# MSS_DCAN register map
Vendor: Texas Instruments
Registers are 32-bit, read-only, no defined reset value unless marked. A register's access mark holds for its fields unless they carry their own. Offsets are as the file gives them; [hi:lo] are bit positions; {n}, {i} and the like mark numbered series; 'fields as' and 'values as' point back to an identical list.

## MSS_DCAN (part 2 of 2)
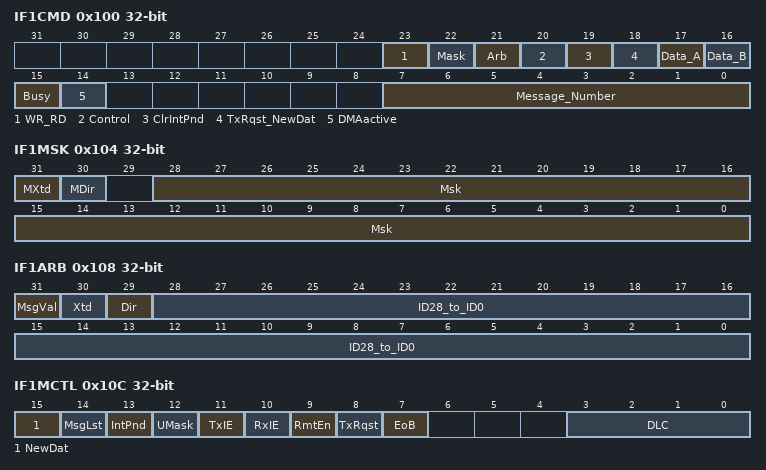
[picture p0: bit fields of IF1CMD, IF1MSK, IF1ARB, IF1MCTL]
0x100 IF1CMD access per field — IF1 Command Register The IF1 Command Register (IF1CMD) configures and initiates the transfer between the IF1 register sets and the message RAM. It is configurable which portions of the message object should be transferred. A transfer is started when the CPU writes the message number to bits [7:0] of the IF1 command register. With this write operation, the Busy bit is automatically set to '1' to indicate that a transfer is in progress. After 4 to 14 OCP clock cycles, the transfer between the interface register and the message RAM will be completed and the Busy bit is cleared. The maximum number of cycles is needed when the message transfer concurs with a CAN message transmission, acceptance filtering, or message storage. If the CPU writes to both IF1 command registers consecutively (request of a second transfer while first transfer is still in progress), the second transfer will start after the first one has been completed. While Busy bit is one, IF1 register sets are write protected. For debug support, the auto clear functionality of the IF1 command registers (clear of DMAactive flag by r/w) is disabled during Debug/Suspend mode. If an invalid Message Number is written to bits [7:0] of the IF1 command register, the message handler may access an implemented (valid) message object instead.
  [23] WR_RD rw — Write/Read
    1=en_2_0x1 (Direction = Write: Transfer direction is from the IF1 register set to the message object addressed by Message Number (Bits [7:0]).); 0=en_1_0x0 (Direction = Read: Transfer direction is from the message object addressed by Message Number (Bits [7:0]) to the IF1 register set.)
  [22] Mask rw — Access mask bits
    1=en_2_0x1 (Direction = Read: The mask bits (identifier mask + MDir + MXtd) will be transferred from the message object addressed by Message Number (Bits [7:0]) to the IF1 register set. Direction = Write: The mask bits (identifier mask + MDir + MXtd) will be transferred from the IF1 register set to the message object addressed by Message Number (Bits [7:0]).); 0=en_1_0x0 (Mask bits will not be changed)
  [21] Arb rw — Access arbitration bits
    1=en_2_0x1 (Direction = Read: The Arbitration bits (Identifier + Dir + Xtd + MsgVal) will be transferred from the message object addressed by Message Number (Bits [7:0]) to the corresponding IF1 register set. Direction = Write: The Arbitration bits (Identifier + Dir + Xtd + MsgVal) will be transferred from the IF1 register set to the message object addressed by Message Number (Bits [7:0]).); 0=en_1_0x0 (Arbitration bits will not be changed)
  [20] Control rw — Access control bits. If the TxRqst/NewDat bit in this register(Bit [18]) is set, the TxRqst/ NewDat bit in the IF1 message control register will be ignored.
    1=en_2_0x1 (Direction = Read: The message control bits will be transferred from the message object addressed by message number (Bits [7:0]) to the IF1 register set. Direction = Write: The message control bits will be transferred from the IF1 register set to the message object addressed by message number (Bits [7:0]).); 0=en_1_0x0 (Control bits will not be changed)
  [19] ClrIntPnd rw — Clear interrupt pending bit
    1=en_2_0x1 (Direction = Read: Clears IntPnd bit in the message object. Direction = Write: This bit is ignored. Copying of IntPnd flag from IF1 Registers to message RAM can only be controlled by the control flag (Bit [20]).); 0=en_1_0x0 (IntPnd bit will not be changed)
  [18] TxRqst_NewDat rw — Access transmission request bit. Note: If a CAN transmission is requested by setting TxRqst/NewDat in this register, the TxRqst/NewDat bits in the message object will be set to one independent of the values in IF1 message control Register. Note: A read access to a message object can be combined with the reset of the control bits IntPnd and NewDat. The values of these bits transferred to the IF1 message control register always reflect the status before resetting them.
    1=en_2_0x1 (Direction = Read: Clears NewDat bit in the message object. Direction = Write: Sets TxRqst/NewDat in message object.); 0=en_1_0x0 (Direction = Read: NewDat bit will not be changed. Direction = Write: TxRqst/NewDat bit will be handled according to the control bit.)
  [17] Data_A rw — Access Data Bytes 0 to 3.
    1=en_2_0x1 (Direction = Read: The data bytes 0-3 will be transferred from the message object addressed by the Message Number (Bits [7:0]) to the corresponding IF1 register set. Direction = Write: The data bytes 0-3 will be transferred from the IF1 register set to the message object addressed by the Message Number (Bits [7:0]). Note: The duration of the message transfer is independent of the number of bytes to be transferred.); 0=en_1_0x0 (Data Bytes 0-3 will not be changed.)
  [16] Data_B rw — Access Data Bytes 4 to 7.
    1=en_2_0x1 (Direction = Read: The data bytes 4-7 will be transferred from the message object addressed by Message Number (Bits [7:0]) to the corresponding IF1 register set. Direction = Write: The data bytes 4-7 will be transferred from the IF1 register set to the message object addressed by message number (Bits [7:0]). Note: The duration of the message transfer is independent of the number of bytes to be transferred.); 0=en_1_0x0 (Data Bytes 4-7 will not be changed.)
  [15] Busy rw — Busy flag. This bit is set to one after the message number has been written to bits 7 to 0. IF1 register set will be write protected. The bit is cleared after read/write action has been finished.
    1=en_2_0x1 (Transfer between IF1 register set and message RAM is in progress.); 0=en_1_0x0 (No transfer between IF1 register set and message RAM is in progress.)
  [14] DMAactive rw — Activation of DMA feature for subsequent internal IF1 update. Note: Due to the auto reset feature of the DMAactive bit, this bit has to be set for each subsequent DMA cycle separately.
    1=en_2_0x1 (DMA is requested after completed transfer between IF1 register set and message RAM. The DMA request remains active until the first read or write to one of the IF1 registers; an exception is a write to Message Number (Bits [7:0]) when DMAactive is one.); 0=en_1_0x0 (DMA request line is independent of IF1 activities.)
  [7:0] Message_Number rw — Number of message object in message RAM which is used for data transfer.
    81=en_5_0x51 (Invalid message numbers (value 81 to FF).); 80=en_4_0x50 (Valid message number.); 1=en_3_0x1 (Valid message numbers (value 01 to 80).); 0=en_2_0x0 (Invalid message numbers.); 0=en_1_0x0 (Invalid message number.)
0x104 IF1MSK access per field — IF1 Mask Register The bits of the IF1 mask registers mirror the mask bits of a message object. While Busy bit of IF1 command register is one, IF1 register set is write protected.
  [31] MXtd rw — Mask Extended Identifier. When 11 bit (standard) identifiers are used for a message object, the identifiers of received data frames are written into bits ID28 to ID18. For acceptance filtering, only these bits together with mask bits Msk28 to Msk18 are considered.
    1=en_2_0x1 (The extended identifier bit (IDE) is used for acceptance filtering.); 0=en_1_0x0 (The extended identifier bit (IDE) has no effect on the acceptance filtering.)
  [30] MDir rw — Mask Message Direction
    1=en_2_0x1 (The message direction bit (Dir) is used for acceptance filtering.); 0=en_1_0x0 (The message direction bit (Dir) has no effect on the acceptance filtering.)
  [28:0] Msk rw — Identifier Mask
    1=en_2_0x1 (The corresponding bit in the identifier of the message object is used for acceptance filtering.); 0=en_1_0x0 (The corresponding bit in the identifier of the message object is not used for acceptance filtering (don't care).)
0x108 IF1ARB rw — IF1 Arbitration Register The bits of the IF1 arbitration registers mirror the arbitration bits of a message object. While Busy bit of IF1 command register is one, IF1 register set is write protected.
  [31] MsgVal — Message valid. The CPU should reset the MsgVal bit of all unused Messages Objects during the initialization before it resets bit Init in the CAN control register. This bit must also be reset before the identifier ID28 to ID0, the control bits Xtd, Dir or DLC3 to DLC0 are modified, or if the messages object is no longer required.
    1=en_2_0x1 (The message object is to be used by the message handler.); 0=en_1_0x0 (The message object is ignored by the message handler.)
  [30] Xtd — Extended identifier
    1=en_2_0x1 (The 29-bit (extended) Identifier is used for this message object.); 0=en_1_0x0 (The 11-bit (standard) Identifier is used for this message object.)
  [29] Dir — Message direction
    1=en_2_0x1 (Direction = transmit: On TxRqst, the respective message object is transmitted as a data frame. On reception of a remote frame with matching identifier, the TxRqst bit of this message object is set (if RmtEn = 1).); 0=en_1_0x0 (Direction = receive: On TxRqst, a remote frame with the identifier of this message object is transmitted. On reception of a data frame with matching identifier, this message is stored in this message object.)
  [28:0] ID28_to_ID0 — Message identifier. ID28 to ID0 is equal to 29 bit identifier (extended frame) ID28 to ID18 is equal to 11 bit identifier (standard frame)
0x10C IF1MCTL rw — IF1 Message Control Register The bits of the IF1 message control registers mirror the message control bits of a message object. While Busy bit of IF1 command register is one, IF1 register set is write protected.
  [15] NewDat — New data
    1=en_2_0x1 (The message handler or the CPU has written new data into the data portion of this message object.); 0=en_1_0x0 (No new data has been written into the data portion of this message object by the message handler since the last time when this flag was cleared by the CPU.)
  [14] MsgLst — Message lost (only valid for message objects with direction = receive)
    1=en_2_0x1 (The message handler stored a new message into this object when NewDat was still set, so the previous message has been overwritten.); 0=en_1_0x0 (No message lost since the last time when this bit was reset by the CPU.)
  [13] IntPnd — Interrupt pending
    1=en_2_0x1 (This message object is the source of an interrupt. The Interrupt Identifier in the interrupt register will point to this message object if there is no other interrupt source with higher priority.); 0=en_1_0x0 (This message object is not the source of an interrupt.)
  [12] UMask — Use acceptance mask. If the UMask bit is set to one, the message object's mask bits have to be programmed during initialization of the message object before MsgVal is set to one.
    1=en_2_0x1 (Use mask (Msk[28:0], MXtd, and MDir) for acceptance filtering); 0=en_1_0x0 (Mask ignored)
  [11] TxIE — Transmit interrupt enable
    1=en_2_0x1 (IntPnd will be triggered after the successful transmission of a frame.); 0=en_1_0x0 (IntPnd will not be triggered after the successful transmission of a frame.)
  [10] RxIE — Receive interrupt enable
    1=en_2_0x1 (IntPnd will be triggered after the successful reception of a frame.); 0=en_1_0x0 (IntPnd will not be triggered after the successful reception of a frame.)
  [9] RmtEn — Remote enable
    1=en_2_0x1 (At the reception of a remote frame, TxRqst is set.); 0=en_1_0x0 (At the reception of a remote frame, TxRqst is not changed.)
  [8] TxRqst — Transmit request
    1=en_2_0x1 (The transmission of this message object is requested and is not yet done.); 0=en_1_0x0 (This message object is not waiting for a transmission.)
  [7] EoB — Data frame has 0 to 8 data bits. Note: This bit is used to concatenate multiple message objects to build a FIFO Buffer. For single message objects (not belonging to a FIFO Buffer), this bit must always be set to one.
    1=en_2_0x1 (Note: The data length code of a message object must be defined the same as in all the corresponding objects with the same identifier at other nodes. When the message handler stores a data frame, it will write the DLC to the value given by the received message.); 0=en_1_0x0 (Data frame has 8 data bytes.)
  [3:0] DLC — Data length code. Note: The data length code of a message object must be defined the same as in all the corresponding objects with the same identifier at other nodes. When the message handler stores a data frame, it will write the DLC to the value given by the received message.
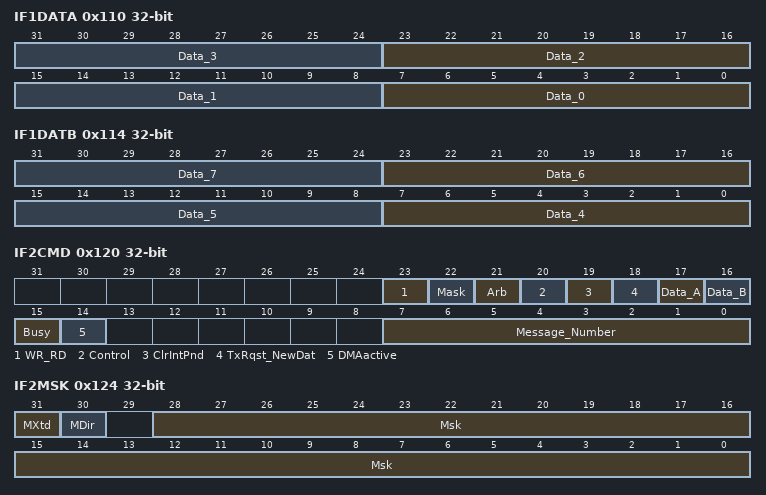
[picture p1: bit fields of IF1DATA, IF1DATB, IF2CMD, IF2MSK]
0x110 IF1DATA rw — IF1 Data A Register The data bytes of CAN messages are stored in the IF1 registers in the following order: (1) In a CAN data frame, Data 0 is the first, and Data 7 is the last byte to be transmitted or received. (2) In CAN's serial bit stream, the MSB of each byte will be transmitted first.
  [8n+7:8n] Data_{n} (n=0..3)
0x114 IF1DATB rw — IF1 Data B Register The data bytes of CAN messages are stored in the IF1 registers in the following order: (1) In a CAN data frame, Data 0 is the first, and Data 7 is the last byte to be transmitted or received. (2) In CAN's serial bit stream, the MSB of each byte will be transmitted first.
  [8n-25:8n-32] Data_{n} (n=4..7)
0x120 IF2CMD access per field — IF2 Command Register The IF2 Command Register (IF1CMD) configures and initiates the transfer between the IF2 register sets and the message RAM. It is configurable which portions of the message object should be transferred. A transfer is started when the CPU writes the message number to bits [7:0] of the IF2 command register. With this write operation, the Busy bit is automatically set to '1' to indicate that a transfer is in progress. After 4 to 14 OCP clock cycles, the transfer between the interface register and the message RAM will be completed and the Busy bit is cleared. The maximum number of cycles is needed when the message transfer concurs with a CAN message transmission, acceptance filtering, or message storage. If the CPU writes to both IF2 command registers consecutively (request of a second transfer while first transfer is still in progress), the second transfer will start after the first one has been completed. While Busy bit is one, IF2 register sets are write protected. For debug support, the auto clear functionality of the IF2 command registers (clear of DMAactive flag by r/w) is disabled during Debug/Suspend mode. If an invalid Message Number is written to bits [7:0] of the IF2 command register, the message handler may access an implemented (valid) message object instead.
  [23] WR_RD rw — Write/Read
    1=en_2_0x1 (Direction = Write: Transfer direction is from the IF2 register set to the message object addressed by Message Number (Bits [7:0]).); 0=en_1_0x0 (Direction = Read: Transfer direction is from the message object addressed by Message Number (Bits [7:0]) to the IF2 register set.)
  [22] Mask rw — Access mask bits
    1=en_2_0x1 (Direction = Read: The mask bits (identifier mask + MDir + MXtd) will be transferred from the message object addressed by Message Number (Bits [7:0]) to the IF2 register set. Direction = Write: The mask bits (identifier mask + MDir + MXtd) will be transferred from the IF2 register set to the message object addressed by Message Number (Bits [7:0]).); 0=en_1_0x0 (Mask bits will not be changed)
  [21] Arb rw — Access arbitration bits
    1=en_2_0x1 (Direction = Read: The Arbitration bits (Identifier + Dir + Xtd + MsgVal) will be transferred from the message object addressed by Message Number (Bits [7:0]) to the corresponding IF2 register set. Direction = Write: The Arbitration bits (Identifier + Dir + Xtd + MsgVal) will be transferred from the IF2 register set to the message object addressed by Message Number (Bits [7:0]).); 0=en_1_0x0 (Arbitration bits will not be changed)
  [20] Control rw — Access control bits. If the TxRqst/NewDat bit in this register(Bit [18]) is set, the TxRqst/ NewDat bit in the IF2 message control register will be ignored.
    1=en_2_0x1 (Direction = Read: The message control bits will be transferred from the message object addressed by message number (Bits [7:0]) to the IF2 register set. Direction = Write: The message control bits will be transferred from the IF2 register set to the message object addressed by message number (Bits [7:0]).); 0=en_1_0x0 (Control bits will not be changed)
  [19] ClrIntPnd rw — Clear interrupt pending bit
    1=en_2_0x1 (Direction = Read: Clears IntPnd bit in the message object. Direction = Write: This bit is ignored. Copying of IntPnd flag from IF2 Registers to message RAM can only be controlled by the control flag (Bit [20]).); 0=en_1_0x0 (IntPnd bit will not be changed)
  [18] TxRqst_NewDat rw — Access transmission request bit. Note: If a CAN transmission is requested by setting TxRqst/NewDat in this register, the TxRqst/NewDat bits in the message object will be set to one independent of the values in IF2 message control Register. Note: A read access to a message object can be combined with the reset of the control bits IntPnd and NewDat. The values of these bits transferred to the IF2 message control register always reflect the status before resetting them.
    values as IF1CMD.TxRqst_NewDat
  [17] Data_A rw — Access Data Bytes 0 to 3.
    1=en_2_0x1 (Direction = Read: The data bytes 0-3 will be transferred from the message object addressed by the Message Number (Bits [7:0]) to the corresponding IF2 register set. Direction = Write: The data bytes 0-3 will be transferred from the IF2 register set to the message object addressed by the Message Number (Bits [7:0]). Note: The duration of the message transfer is independent of the number of bytes to be transferred.); 0=en_1_0x0 (Data Bytes 0-3 will not be changed.)
  [16] Data_B rw — Access Data Bytes 4 to 7.
    1=en_2_0x1 (Direction = Read: The data bytes 4-7 will be transferred from the message object addressed by Message Number (Bits [7:0]) to the corresponding IF2 register set. Direction = Write: The data bytes 4-7 will be transferred from the IF2 register set to the message object addressed by message number (Bits [7:0]). Note: The duration of the message transfer is independent of the number of bytes to be transferred.); 0=en_1_0x0 (Data Bytes 4-7 will not be changed.)
  [15] Busy rw — Busy flag. This bit is set to one after the message number has been written to bits 7 to 0. IF2 register set will be write protected. The bit is cleared after read/write action has been finished.
    1=en_2_0x1 (Transfer between IF2 register set and message RAM is in progress.); 0=en_1_0x0 (No transfer between IF2 register set and message RAM is in progress.)
  [14] DMAactive rw — Activation of DMA feature for subsequent internal IF2 update. Note: Due to the auto reset feature of the DMAactive bit, this bit has to be set for each subsequent DMA cycle separately.
    1=en_2_0x1 (DMA is requested after completed transfer between IF2 register set and message RAM. The DMA request remains active until the first read or write to one of the IF2 registers; an exception is a write to Message Number (Bits [7:0]) when DMAactive is one.); 0=en_1_0x0 (DMA request line is independent of IF2 activities.)
  [7:0] Message_Number rw — Number of message object in message RAM which is used for data transfer.
    81=en_5_0x51 (Invalid message numbers (values 81 to FF).); 80=en_4_0x50 (Valid message number.); 1=en_3_0x1 (Valid message numbers (values 01 to 80).); 0=en_2_0x0 (Invalid message number.); 0=en_1_0x0 (Invalid message number.)
0x124 IF2MSK access per field — IF2 Mask Register The bits of the IF2 mask registers mirror the mask bits of a message object. While Busy bit of IF2 command register is one, IF2 register set is write protected.
  fields as IF1MSK
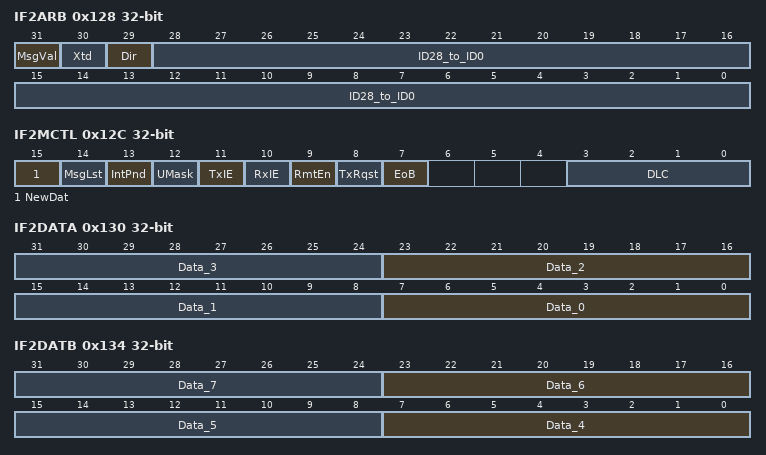
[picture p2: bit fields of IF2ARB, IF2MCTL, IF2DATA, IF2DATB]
0x128 IF2ARB rw — IF2 Arbitration Register The bits of the IF2 arbitration registers mirror the arbitration bits of a message object. While Busy bit of IF2 command register is one, IF2 register set is write protected.
  [31] MsgVal — Message valid. The CPU should reset the MsgVal bit of all unused Messages Objects during the initialization before it resets bit Init in the CAN control register. This bit must also be reset before the identifier ID28 to ID0, the control bits Xtd, Dir or DLC3 to DLC0 are modified, or if the messages object is no longer required.
    values as IF1ARB.MsgVal
  [30] Xtd — Extended identifier
    values as IF1ARB.Xtd
  [29] Dir — Message direction
    values as IF1ARB.Dir
  [28:0] ID28_to_ID0 — Message identifier. ID28 to ID0 is equal to 29-bit identifier (extended frame) ID28 to ID18 is equal to 11-bit identifier (standard frame)
0x12C IF2MCTL rw — IF2 Message Control Register The bits of the IF2 message control registers mirror the message control bits of a message object. While Busy bit of IF2 command register is one, IF2 register set is write protected.
  fields as IF1MCTL
0x130 IF2DATA rw — IF2 Data A Register The data bytes of CAN messages are stored in the IF2 registers in the following order: (1) In a CAN data frame, Data 0 is the first, and Data 7 is the last byte to be transmitted or received. (2) In CAN's serial bit stream, the MSB of each byte will be transmitted first.
  [8n+7:8n] Data_{n} (n=0..3)
0x134 IF2DATB rw — IF2 Data B Register The data bytes of CAN messages are stored in the IF2 registers in the following order: (1) In a CAN data frame, Data 0 is the first, and Data 7 is the last byte to be transmitted or received. (2) In CAN's serial bit stream, the MSB of each byte will be transmitted first.
  [8n-25:8n-32] Data_{n} (n=4..7)
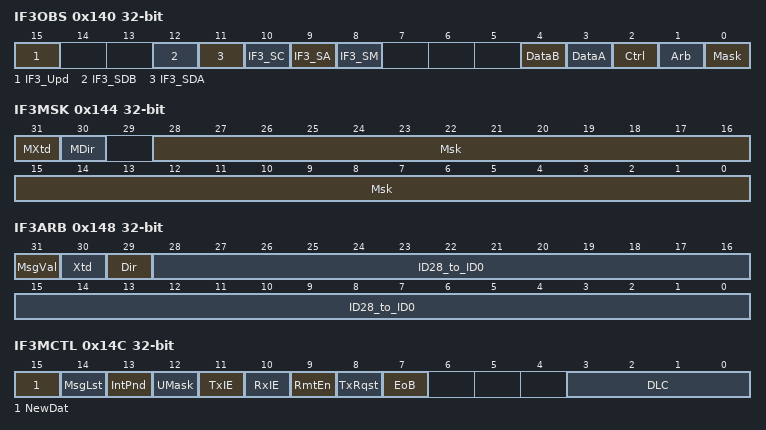
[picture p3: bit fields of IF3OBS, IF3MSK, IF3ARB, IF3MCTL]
0x140 IF3OBS access per field — IF3 Observation Register The IF3 register set can automatically be updated with received message objects without the need to initiate the transfer from message RAM by CPU. The observation flags (Bits [4:0]) in the IF3 observation register are used to determine, which data sections of the IF3 interface register set have to be read in order to complete a DMA read cycle. After all marked data sections are read, the DCAN is enabled to update the IF3 interface register set with new data. Any access order of single bytes or half-words is supported. When using byte or half-word accesses, a data section is marked as completed, if all bytes are read. Note: If IF3 Update Enable is used and no Observation flag is set, the corresponding message objects will be copied to IF3 without activating the DMA request line and without waiting for DMA read accesses. A write access to this register aborts a pending DMA cycle by resetting the DMA line and enables updating of IF3 interface register set with new data. To avoid data inconsistency, the DMA controller should be disabled before reconfiguring IF3 observation register. The status of the current read-cycle can be observed via status flags (Bits [12:8]). If an interrupt line is available for IF3, an interrupt will be generated by IF3Upd flag. See the device-specific data sheet for the availability of this interrupt source. With this interrupt, the observation status bits and the IF3Upd bit could be used by the application to realize the notification about new IF3 content in polling or interrupt mode.
  [15] IF3_Upd ro — IF3 Update Data
    1=en_2_0x1 (New data has been loaded since last IF3 read.); 0=en_1_0x0 (No new data has been loaded since last IF3 read.)
  [12] IF3_SDB ro — IF3 Status of Data B read access
    1=en_2_0x1 (Data B section has still data to be read out.); 0=en_1_0x0 (All Data B bytes are already read out, or are not marked to be read.)
  [11] IF3_SDA ro — IF3 Status of Data A read access
    1=en_2_0x1 (Data A section has still data to be read out.); 0=en_1_0x0 (All Data A bytes are already read out, or are not marked to be read.)
  [10] IF3_SC ro — IF3 Status of control bits read access
    1=en_2_0x1 (Control section has still data to be read out.); 0=en_1_0x0 (All control section bytes are already read out, or are not marked to be read.)
  [9] IF3_SA ro — IF3 Status of Arbitration data read access
    1=en_2_0x1 (Arbitration section has still data to be read out.); 0=en_1_0x0 (All Arbitration data bytes are already read out, or are not marked to be read.)
  [8] IF3_SM ro — IF3 Status of Mask data read access
    1=en_2_0x1 (Mask section has still data to be read out.); 0=en_1_0x0 (All mask data bytes are already read out, or are not marked to be read.)
  [4] DataB rw — Data B read observation
    1=en_2_0x1 (Data B section has to be read to enable next IF3 update.); 0=en_1_0x0 (Data B section has not to be read.)
  [3] DataA rw — Data A read observation
    1=en_2_0x1 (Data A section has to be read to enable next IF3 update.); 0=en_1_0x0 (Data A section has not to be read.)
  [2] Ctrl rw — Ctrl read observation
    1=en_2_0x1 (Ctrl section has to be read to enable next IF3 update.); 0=en_1_0x0 (Ctrl section has not to be read.)
  [1] Arb rw — Arbitration data read observation
    1=en_2_0x1 (Arbitration data has to be read to enable next IF3 update.); 0=en_1_0x0 (Arbitration data has not to be read.)
  [0] Mask rw — Mask data read observation
    1=en_2_0x1 (Mask data has to be read to enable next IF3 update.); 0=en_1_0x0 (Mask data has not to be read.)
0x144 IF3MSK access per field — IF3 Mask Register
  [31] MXtd ro — Mask Extended Identifier. When 11 bit (standard) identifiers are used for a message object, the identifiers of received data frames are written into bits ID28 to ID18. For acceptance filtering, only these bits together with mask bits Msk28 to Msk18 are considered.
    values as IF1MSK.MXtd
  [30] MDir ro — Mask Message Direction
    values as IF1MSK.MDir
  [28:0] Msk rw — Identifier Mask
    values as IF1MSK.Msk
0x148 IF3ARB — IF3 Arbitration Register
  [31] MsgVal — Message Valid. The CPU should reset the MsgVal bit of all unused Messages Objects during the initialization before it resets bit Init in the CAN control register. This bit must also be reset before the identifier ID28 to ID0, the control bits Xtd, Dir or DLC3 to DLC0 are modified, or if the messages object is no longer required.
    values as IF1ARB.MsgVal
  [30] Xtd — Extended Identifier
    values as IF1ARB.Xtd
  [29] Dir — Message Direction
    values as IF1ARB.Dir
  [28:0] ID28_to_ID0 — Message Identifier. ID28 to ID0 is equal to 29 bit Identifier (extended frame). ID28 to ID18 is equal to 11 bit Identifier (standard frame).
0x14C IF3MCTL — IF3 Message Control Register
  [15] NewDat — New Data
    values as IF1MCTL.NewDat
  [14] MsgLst — Message Lost (only valid for message objects with direction = receive)
    values as IF1MCTL.MsgLst
  [13] IntPnd — Interrupt Pending
    values as IF1MCTL.IntPnd
  [12] UMask — Use Acceptance Mask
    1=en_2_0x1 (Use mask (Msk[28:0], MXtd, and MDir) for acceptance filtering. If the UMask bit is set to one, the message object's mask bits have to be programmed during initialization of the message object before MsgVal is set to one.); 0=en_1_0x0 (Mask ignored)
  [11] TxIE — Transmit Interrupt enable
    values as IF1MCTL.TxIE
  [10] RxIE — Receive Interrupt enable
    values as IF1MCTL.RxIE
  [9] RmtEn — Remote enable
    values as IF1MCTL.RmtEn
  [8] TxRqst — Transmit Request
    values as IF1MCTL.TxRqst
  [7] EoB — Data frame has 0 to 8 data bits. Note: This bit is used to concatenate multiple message objects to build a FIFO Buffer. For single message objects (not belonging to a FIFO Buffer), this bit must always be set to one.
    values as IF1MCTL.EoB
  [3:0] DLC — Data Length Code. Note: The data length code of a message object must be defined the same as in all the corresponding objects with the same identifier at other nodes. When the message handler stores a data frame, it will write the DLC to the value given by the received message.
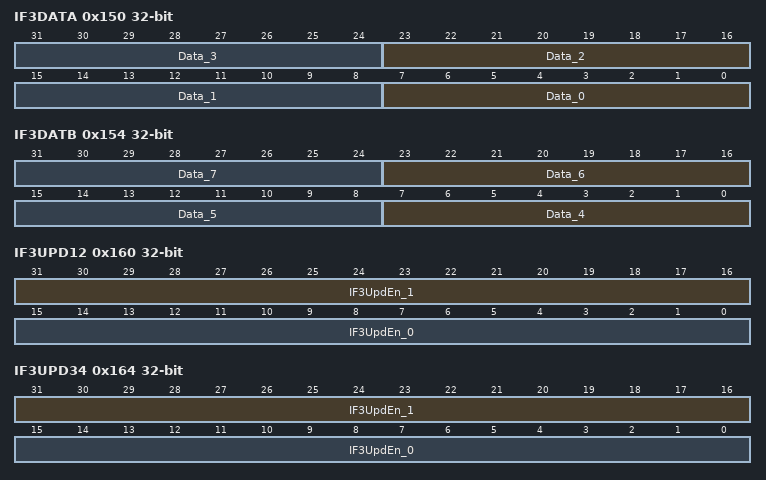
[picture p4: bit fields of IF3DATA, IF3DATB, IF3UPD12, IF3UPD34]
0x150 IF3DATA — IF3 Data A Register The data bytes of CAN messages are stored in the IF3 registers in the following order. In a CAN data frame, Data 0 is the first, and Data 7 is the last byte to be transmitted or received. In CAN's serial bit stream, the MSB of each byte will be transmitted first.
  [8n+7:8n] Data_{n} (n=0..3)
0x154 IF3DATB — IF3 Data B Register The data bytes of CAN messages are stored in the IF3 registers in the following order. In a CAN data frame, Data 0 is the first, and Data 7 is the last byte to be transmitted or received. In CAN's serial bit stream, the MSB of each byte will be transmitted first.
  [8n-25:8n-32] Data_{n} (n=4..7)
0x160 IF3UPD12 rw — IF3 Update Enable Register The automatic update functionality of the IF3 register set can be configured for each message object. A message object is enabled for automatic IF3 update, if the dedicated IF3UpdEn flag is set. This means that an active NewDat flag of this message object (e.g due to reception of a CAN frame) will trigger an automatic copy of the whole message object to IF3 register set. IF3 Update enable should not be set for transmit objects.
  [31:16] IF3UpdEn_1 — IF3 Update Enabled (for all message objects)
    1=en_2_0x1 (Automatic IF3 update is enabled for this message object. A message object is scheduled to be copied to IF3 register set, if NewDat flag of the message object is active.); 0=en_1_0x0 (Automatic IF3 update is disabled for this message object.)
  [15:0] IF3UpdEn_0 — IF3 Update Enabled (for all message objects)
    values as IF3UpdEn_1
0x164 IF3UPD34 rw — IF3 Update Enable Register The automatic update functionality of the IF3 register set can be configured for each message object. A message object is enabled for automatic IF3 update, if the dedicated IF3UpdEn flag is set. This means that an active NewDat flag of this message object (e.g due to reception of a CAN frame) will trigger an automatic copy of the whole message object to IF3 register set. IF3 Update enable should not be set for transmit objects.
  fields as IF3UPD12
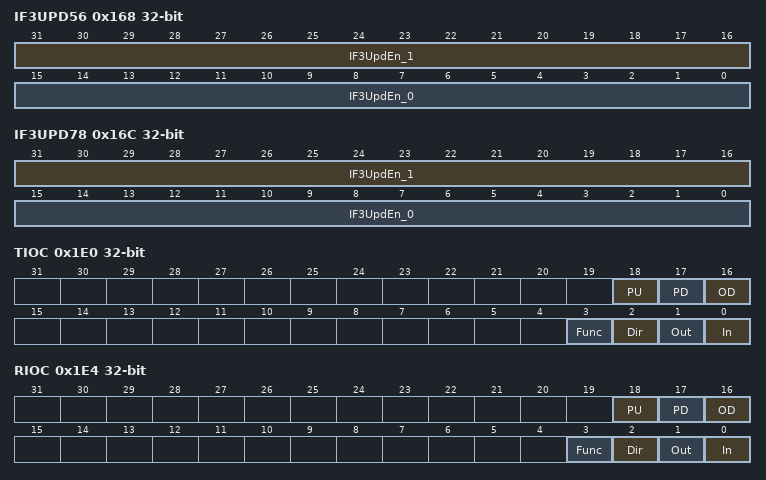
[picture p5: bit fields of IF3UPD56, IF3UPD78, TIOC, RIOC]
0x168 IF3UPD56 rw — IF3 Update Enable Register The automatic update functionality of the IF3 register set can be configured for each message object. A message object is enabled for automatic IF3 update, if the dedicated IF3UpdEn flag is set. This means that an active NewDat flag of this message object (e.g due to reception of a CAN frame) will trigger an automatic copy of the whole message object to IF3 register set. IF3 Update enable should not be set for transmit objects.
  fields as IF3UPD12
0x16C IF3UPD78 rw — IF3 Update Enable Register The automatic update functionality of the IF3 register set can be configured for each message object. A message object is enabled for automatic IF3 update, if the dedicated IF3UpdEn flag is set. This means that an active NewDat flag of this message object (e.g due to reception of a CAN frame) will trigger an automatic copy of the whole message object to IF3 register set. IF3 Update enable should not be set for transmit objects.
  fields as IF3UPD12
0x1E0 TIOC access per field — CAN TX IO Control Register The CAN_TX pin of the DCAN module can be used as general purpose IO pin if CAN function is not needed. The values of the IO control registers are only writable if Init bit of the CAN control register is set. The OD, Func, Dir and Out bits of the CAN TX IO control register are forced to certain values when Init bit of CAN control register is reset (see bit descriptions).
  [18] PU rw — CAN_TX pull up/pull down select. This bit is only active when CAN_TX is configured to be an input.
    1=en_2_0x1 (CAN_TX pull up is selected, when pull logic is active (PD = 0).); 0=en_1_0x0 (CAN_TX pull down is selected, when pull logic is active (PD = 0).)
  [17] PD rw — CAN_TX pull disable. This bit is only active when CAN_TX is configured to be an input.
    1=en_2_0x1 (CAN_TX pull is disabled); 0=en_1_0x0 (CAN_TX pull is active)
  [16] OD rw — CAN_TX open drain enable. This bit is only active when CAN_TX is configured to be in GIO mode (TIOC.Func=0). Forced to '0' if Init bit of CAN control register is reset.
    1=en_2_0x1 (The CAN_TX pin is configured in open drain mode.); 0=en_1_0x0 (The CAN_TX pin is configured in push/pull mode.)
  [3] Func rw — CAN_TX function. This bit changes the function of the CAN_TX pin. Forced to '1' if Init bit of CAN control register is reset.
    1=en_2_0x1 (CAN_TX pin is in functional mode (as an output to transmit CAN data).); 0=en_1_0x0 (CAN_TX pin is in GIO mode.)
  [2] Dir rw — CAN_TX data direction. This bit controls the direction of the CAN_TX pin when it is configured to be in GIO mode only (TIOC.Func=0). Forced to '1' if Init bit of CAN control register is reset.
    1=en_2_0x1 (The CAN_TX pin is an output); 0=en_1_0x0 (The CAN_TX pin is an input.)
  [1] Out rw — CAN_TX data out write. This bit is only active when CAN_TX pin is configured to be in GIO mode (TIOC.Func = 0) and configured to be an output pin (TIOC.Dir = 1). The value of this bit indicates the value to be output to the CAN_TX pin. Forced to Tx output of the CAN core, if Init bit of CAN control register is reset.
    1=en_2_0x1 (The CAN_TX pin is driven to logic high); 0=en_1_0x0 (The CAN_TX pin is driven to logic low)
  [0] In ro — CAN_TX data in. Note: When CAN_TX pin is connected to a CAN transceiver, an external pullup resistor has to be used to ensure that the CAN bus will not be disturbed (e.g. while reset of the DCAN module).
    1=en_2_0x1 (The CAN_TX pin is at logic high); 0=en_1_0x0 (The CAN_TX pin is at logic low)
0x1E4 RIOC access per field — CAN RX IO Control Register The CAN_RX pin of the DCAN module can be used as general purpose IO pin if CAN function is not needed. The values of the IO control registers are writable only if Init bit of CAN control register is set. The OD, Func and Dir bits of the CAN RX IO control register are forced to certain values when the Init bit of CAN control register is reset (see bit descriptions).
  [18] PU rw — CAN_RX pull up/pull down select. This bit is only active when CAN_RX is configured to be an input.
    1=en_2_0x1 (CAN_T=RX pull up is selected, when pull logic is active(PD = 0).); 0=en_1_0x0 (CAN_RX pull down is selected, when pull logic is active (PD = 0).)
  [17] PD rw — CAN_RX pull disable. This bit is only active when CAN_TX is configured to be an input.
    1=en_2_0x1 (CAN_RX pull is disabled); 0=en_1_0x0 (CAN_RX pull is active)
  [16] OD rw — CAN_RX open drain enable. This bit is only active when CAN_RX is configured to be in GIO mode (TIOC.Func=0). Forced to '0' if Init bit of CAN control register is reset.
    1=en_2_0x1 (The CAN_RX pin is configured in open drain mode.); 0=en_1_0x0 (The CAN_RX pin is configured in push/pull mode.)
  [3] Func rw — CAN_RX function. This bit changes the function of the CAN_RX pin. Forced to '1' if Init bit of CAN control register is reset.
    1=en_2_0x1 (CAN_RX pin is in functional mode (as an output to transmit CAN data).); 0=en_1_0x0 (CAN_RX pin is in GIO mode.)
  [2] Dir rw — CAN_RX data direction. This bit controls the direction of the CAN_RX pin when it is configured to be in GIO mode only (TIOC.Func=0). Forced to '1' if Init bit of CAN control register is reset.
    1=en_2_0x1 (The CAN_RX pin is an output); 0=en_1_0x0 (The CAN_RX pin is an input.)
  [1] Out rw — CAN_RX data out write. This bit is only active when CAN_RX pin is configured to be in GIO mode (TIOC.Func = 0) and configured to be an output pin (TIOC.Dir = 1). The value of this bit indicates the value to be output to the CAN_RX pin. Forced to Tx output of the CAN core, if Init bit of CAN control register is reset.
    1=en_2_0x1 (The CAN_RX pin is driven to logic high); 0=en_1_0x0 (The CAN_RX pin is driven to logic low)
  [0] In ro — CAN_RX data in. Note: When CAN_RX pin is connected to a CAN transceiver, an external pullup resistor has to be used to ensure that the CAN bus will not be disturbed (for example, while reset of the DCAN module).
    1=en_2_0x1 (The CAN_RX pin is at logic high); 0=en_1_0x0 (The CAN_RX pin is at logic low)
